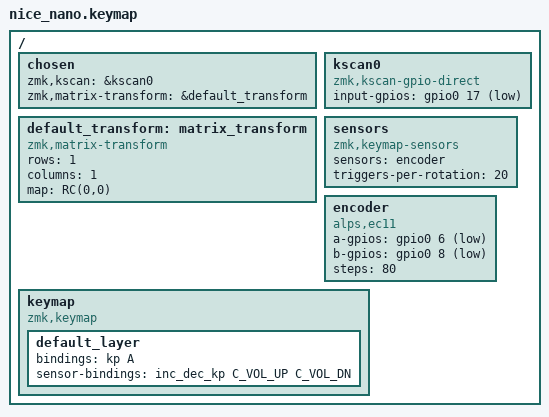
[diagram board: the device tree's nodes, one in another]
#include <behaviors.dtsi>
#include <dt-bindings/zmk/keys.h>
#include <dt-bindings/zmk/matrix_transform.h>

/ {
    chosen {
        zmk,kscan = &kscan0;
        zmk,matrix-transform = &default_transform;
    };

    kscan0: kscan0 {
        compatible = "zmk,kscan-gpio-direct";
        input-gpios = <&gpio0 17 (GPIO_ACTIVE_LOW | GPIO_PULL_UP)>;
    };

    default_transform: matrix_transform {
        compatible = "zmk,matrix-transform";
        rows = <1>;
        columns = <1>;
        map = <RC(0,0)>;
    };

    sensors: sensors {
        compatible = "zmk,keymap-sensors";
        sensors = <&encoder>;
        triggers-per-rotation = <20>;
    };

    encoder: encoder {
        compatible = "alps,ec11";
        a-gpios = <&gpio0 6 (GPIO_ACTIVE_LOW | GPIO_PULL_UP)>;
        b-gpios = <&gpio0 8 (GPIO_ACTIVE_LOW | GPIO_PULL_UP)>;
        steps = <80>;
    };

    keymap {
        compatible = "zmk,keymap";

        default_layer {
            bindings = <&kp A>;
            sensor-bindings = <&inc_dec_kp C_VOL_UP C_VOL_DN>;
        };
    };
};
